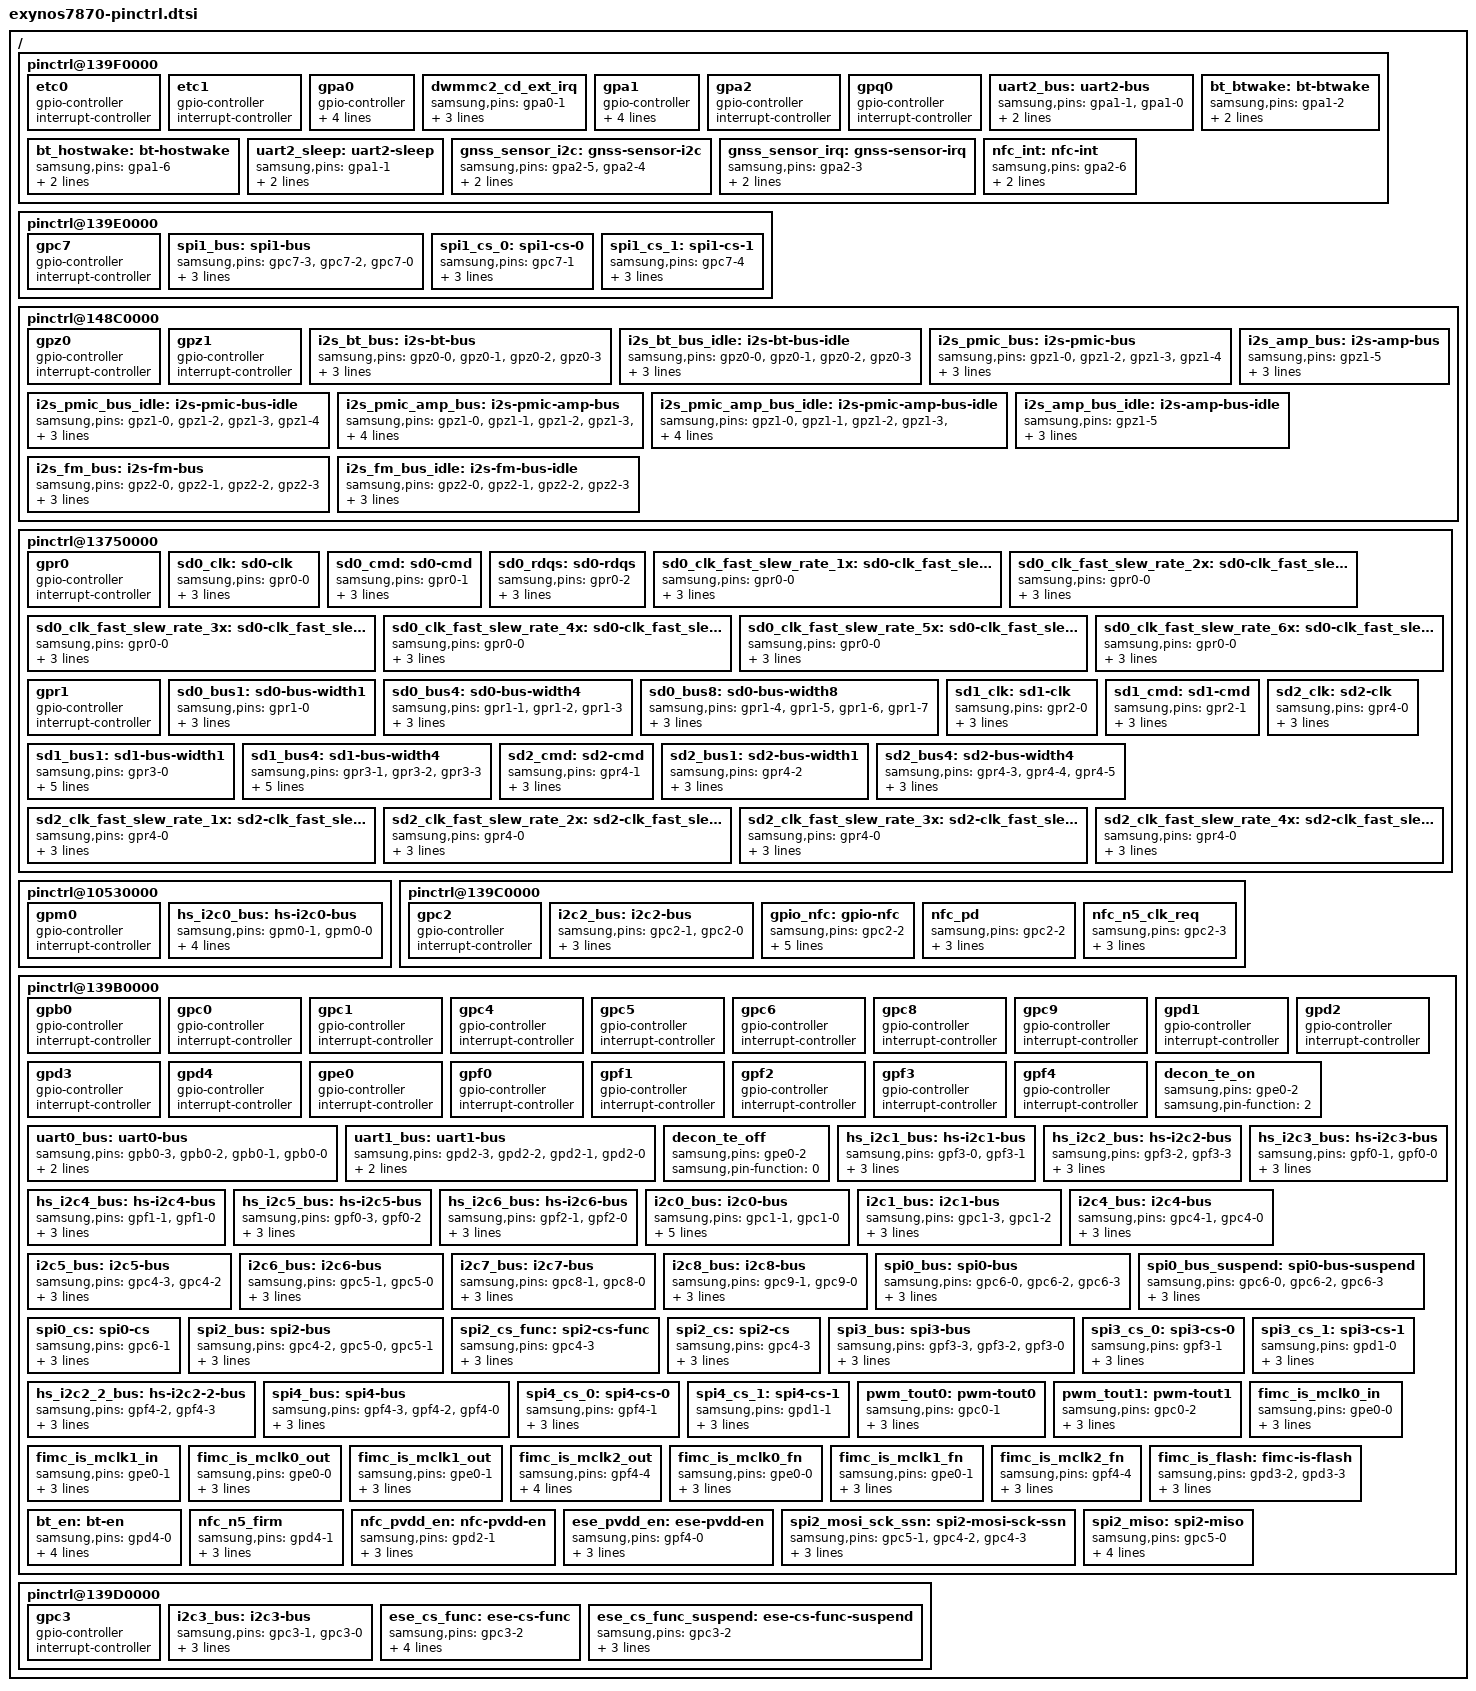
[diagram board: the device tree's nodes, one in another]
/*
 * Samsung's Exynos7870 SoC pin-mux and pin-config device tree source
 *
 * Copyright (c) 2015 Samsung Electronics Co., Ltd.
 *		http://www.samsung.com
 *
 * Samsung's Exynos7870 SoC pin-mux and pin-config options are listed as device
 * tree nodes are listed in this file.
 *
 * This program is free software; you can redistribute it and/or modify
 * it under the terms of the GNU General Public License version 2 as
 * published by the Free Software Foundation.
*/

/ {
	/* ALIVE */
	pinctrl@139F0000 {
		etc0: etc0 {
			gpio-controller;
			#gpio-cells = <2>;

			interrupt-controller;
			#interrupt-cells = <2>;
		};

		etc1: etc1 {
			gpio-controller;
			#gpio-cells = <2>;

			interrupt-controller;
			#interrupt-cells = <2>;
		};

		gpa0: gpa0 {
			gpio-controller;
			#gpio-cells = <2>;

			interrupt-controller;
			#interrupt-cells = <3>;
			interrupt-parent = <&gic>;
			interrupts = <0 0 0>, <0 1 0>, <0 2 0>, <0 3 0>,
				     <0 4 0>, <0 5 0>, <0 6 0>, <0 7 0>;
		};

		dwmmc2_cd_ext_irq: dwmmc2_cd_ext_irq {
			samsung,pins = "gpa0-1";
			samsung,pin-function = <0xf>;
			samsung,pin-pud = <3>;
			samsung,pin-drv = <4>;
		};

		gpa1: gpa1 {
			gpio-controller;
			#gpio-cells = <2>;

			interrupt-controller;
			#interrupt-cells = <3>;
			interrupt-parent = <&gic>;
			interrupts = <0 8 0>, <0 9 0>, <0 10 0>, <0 11 0>,
				     <0 12 0>, <0 13 0>, <0 14 0>, <0 15 0>;
		};

		gpa2: gpa2 {
			gpio-controller;
			#gpio-cells = <2>;

			interrupt-controller;
			#interrupt-cells = <2>;
		};

		gpq0: gpq0 {
			gpio-controller;
			#gpio-cells = <2>;

			interrupt-controller;
			#interrupt-cells = <2>;
		};

		/* UART_DEBUG */
		uart2_bus: uart2-bus {
			samsung,pins = "gpa1-1", "gpa1-0";
			samsung,pin-function = <2>;
			samsung,pin-pud = <0>;
		};

		bt_btwake: bt-btwake {
			samsung,pins = "gpa1-2";
			samsung,pin-function = <1>;
			samsung,pin-pud = <1>;
		};

		bt_hostwake: bt-hostwake {
			samsung,pins = "gpa1-6";
			samsung,pin-function = <0>;
			samsung,pin-pud = <0>;
		};

		uart2_sleep: uart2-sleep {
			samsung,pins = "gpa1-1";
			samsung,pin-function = <0>;
			samsung,pin-pud = <1>;
		};

		gnss_sensor_i2c: gnss-sensor-i2c {
			samsung,pins = "gpa2-5", "gpa2-4";
			samsung,pin-function = <6>;
			samsung,pin-pud = <0>;
		};

		gnss_sensor_irq: gnss-sensor-irq {
			samsung,pins = "gpa2-3";
			samsung,pin-function = <6>;
			samsung,pin-pud = <3>;
		};
		nfc_int: nfc-int {
			samsung,pins = "gpa2-6";
			samsung,pin-function = <0>;
			samsung,pin-pud = <1>;
		};
	};

	pinctrl@139E0000 {
		gpc7: gpc7 {
			gpio-controller;
			#gpio-cells = <2>;

			interrupt-controller;
			#interrupt-cells = <2>;
		};

		spi1_bus: spi1-bus {
			samsung,pins = "gpc7-3", "gpc7-2", "gpc7-0";
			samsung,pin-function = <2>;
			samsung,pin-pud = <3>;
			samsung,pin-drv = <2>;
		};

		spi1_cs_0: spi1-cs-0 {
			samsung,pins = "gpc7-1";
			samsung,pin-function = <1>;
			samsung,pin-pud = <3>;
			samsung,pin-drv = <2>;
		};

		spi1_cs_1: spi1-cs-1 {
			samsung,pins = "gpc7-4";
			samsung,pin-function = <1>;
			samsung,pin-pud = <3>;
			samsung,pin-drv = <0>;
		};
	};


	pinctrl@148C0000 {
		gpz0: gpz0 {
			gpio-controller;
			#gpio-cells = <2>;

			interrupt-controller;
			#interrupt-cells = <2>;
		};

		gpz1: gpz1 {
			gpio-controller;
			#gpio-cells = <2>;

			interrupt-controller;
			#interrupt-cells = <2>;
		};

		i2s_bt_bus: i2s-bt-bus {
			samsung,pins = "gpz0-0", "gpz0-1", "gpz0-2", "gpz0-3";
			samsung,pin-function = <2>;
			samsung,pin-pud = <3>;
			samsung,pin-drv = <2>;
		};

		i2s_bt_bus_idle: i2s-bt-bus-idle {
			samsung,pins = "gpz0-0", "gpz0-1", "gpz0-2", "gpz0-3";
			samsung,pin-function = <0>;
			samsung,pin-pud = <3>;
			samsung,pin-drv = <2>;
		};

		i2s_pmic_bus: i2s-pmic-bus {
			samsung,pins = "gpz1-0", "gpz1-2", "gpz1-3", "gpz1-4";
			samsung,pin-function = <2>;
			samsung,pin-pud = <3>;
			samsung,pin-drv = <5>;
		};

		i2s_pmic_bus_idle: i2s-pmic-bus-idle {
			samsung,pins = "gpz1-0", "gpz1-2", "gpz1-3", "gpz1-4";
			samsung,pin-function = <0>;
			samsung,pin-pud = <3>;
			samsung,pin-drv = <5>;
		};

		i2s_pmic_amp_bus: i2s-pmic-amp-bus {
			samsung,pins = "gpz1-0", "gpz1-1", "gpz1-2", "gpz1-3", "gpz1-4";
			samsung,pin-function = <2>;
			samsung,pin-pud = <3>;
			samsung,pin-drv = <5>;
		};

		i2s_pmic_amp_bus_idle: i2s-pmic-amp-bus-idle {
			samsung,pins = "gpz1-0", "gpz1-1", "gpz1-2", "gpz1-3", "gpz1-4";
			samsung,pin-function = <0>;
			samsung,pin-pud = <3>;
			samsung,pin-drv = <5>;
		};

		i2s_amp_bus: i2s-amp-bus {
			samsung,pins = "gpz1-5";
			samsung,pin-function = <2>;
			samsung,pin-pud = <3>;
			samsung,pin-drv = <2>;
		};

		i2s_amp_bus_idle: i2s-amp-bus-idle {
			samsung,pins = "gpz1-5";
			samsung,pin-function = <0>;
			samsung,pin-pud = <3>;
			samsung,pin-drv = <2>;
		};

		i2s_fm_bus: i2s-fm-bus {
			samsung,pins = "gpz2-0", "gpz2-1", "gpz2-2", "gpz2-3";
			samsung,pin-function = <2>;
			samsung,pin-pud = <0>;
			samsung,pin-drv = <2>;
		};

		i2s_fm_bus_idle: i2s-fm-bus-idle {
			samsung,pins = "gpz2-0", "gpz2-1", "gpz2-2", "gpz2-3";
			samsung,pin-function = <0>;
			samsung,pin-pud = <0>;
			samsung,pin-drv = <2>;
		};
	};

	/* FSYS */
	pinctrl@13750000 {
		gpr0: gpr0 {
			gpio-controller;
			#gpio-cells = <2>;

			interrupt-controller;
			#interrupt-cells = <2>;
		};

		sd0_clk: sd0-clk {
			samsung,pins = "gpr0-0";
			samsung,pin-function = <2>;
			samsung,pin-pud = <0>;
			samsung,pin-drv = <2>;
		};

		sd0_cmd: sd0-cmd {
			samsung,pins = "gpr0-1";
			samsung,pin-function = <2>;
			samsung,pin-pud = <3>;
			samsung,pin-drv = <2>;
		};

		sd0_rdqs: sd0-rdqs {
			samsung,pins = "gpr0-2";
			samsung,pin-function = <2>;
			samsung,pin-pud = <0>;
			samsung,pin-drv = <2>;
		};

		sd0_clk_fast_slew_rate_1x: sd0-clk_fast_slew_rate_1x {
			samsung,pins = "gpr0-0";
			samsung,pin-function = <2>;
			samsung,pin-pud = <0>;
			samsung,pin-drv = <0>;
		};

		sd0_clk_fast_slew_rate_2x: sd0-clk_fast_slew_rate_2x {
			samsung,pins = "gpr0-0";
			samsung,pin-function = <2>;
			samsung,pin-pud = <0>;
			samsung,pin-drv = <1>;
		};

		sd0_clk_fast_slew_rate_3x: sd0-clk_fast_slew_rate_3x {
			samsung,pins = "gpr0-0";
			samsung,pin-function = <2>;
			samsung,pin-pud = <0>;
			samsung,pin-drv = <2>;
		};

		sd0_clk_fast_slew_rate_4x: sd0-clk_fast_slew_rate_4x {
			samsung,pins = "gpr0-0";
			samsung,pin-function = <2>;
			samsung,pin-pud = <0>;
			samsung,pin-drv = <3>;
		};

		sd0_clk_fast_slew_rate_5x: sd0-clk_fast_slew_rate_5x {
			samsung,pins = "gpr0-0";
			samsung,pin-function = <2>;
			samsung,pin-pud = <0>;
			samsung,pin-drv = <4>;
		};

		sd0_clk_fast_slew_rate_6x: sd0-clk_fast_slew_rate_6x {
			samsung,pins = "gpr0-0";
			samsung,pin-function = <2>;
			samsung,pin-pud = <0>;
			samsung,pin-drv = <5>;
		};

		gpr1: gpr1 {
			gpio-controller;
			#gpio-cells = <2>;

			interrupt-controller;
			#interrupt-cells = <2>;
		};

		sd0_bus1: sd0-bus-width1 {
			samsung,pins = "gpr1-0";
			samsung,pin-function = <2>;
			samsung,pin-pud = <3>;
			samsung,pin-drv = <2>;
		};

		sd0_bus4: sd0-bus-width4 {
			samsung,pins = "gpr1-1", "gpr1-2", "gpr1-3";
			samsung,pin-function = <2>;
			samsung,pin-pud = <3>;
			samsung,pin-drv = <2>;
		};

		sd0_bus8: sd0-bus-width8 {
			samsung,pins = "gpr1-4", "gpr1-5", "gpr1-6", "gpr1-7";
			samsung,pin-function = <2>;
			samsung,pin-pud = <3>;
			samsung,pin-drv = <2>;
		};

		sd1_clk: sd1-clk {
			samsung,pins = "gpr2-0";
			samsung,pin-function = <2>;
			samsung,pin-pud = <0>;
			samsung,pin-drv = <2>;
		};

		sd1_cmd: sd1-cmd {
			samsung,pins = "gpr2-1";
			samsung,pin-function = <2>;
			samsung,pin-pud = <0>;
			samsung,pin-drv = <2>;
		};

		sd1_bus1: sd1-bus-width1 {
			samsung,pins = "gpr3-0";
			samsung,pin-function = <2>;
			samsung,pin-pud = <3>;
			samsung,pin-drv = <2>;
			samsung,pin-con-pdn = <2>;
			samsung,pin-pud-pdn = <3>;
		};

		sd1_bus4: sd1-bus-width4 {
			samsung,pins = "gpr3-1", "gpr3-2", "gpr3-3";
			samsung,pin-function = <2>;
			samsung,pin-pud = <3>;
			samsung,pin-drv = <2>;
			samsung,pin-con-pdn = <2>;
			samsung,pin-pud-pdn = <3>;
		};

		sd2_clk: sd2-clk {
			samsung,pins = "gpr4-0";
			samsung,pin-function = <2>;
			samsung,pin-pud = <0>;
			samsung,pin-drv = <2>;
		};

		sd2_cmd: sd2-cmd {
			samsung,pins = "gpr4-1";
			samsung,pin-function = <2>;
			samsung,pin-pud = <3>;
			samsung,pin-drv = <2>;
		};

		sd2_bus1: sd2-bus-width1 {
			samsung,pins = "gpr4-2";
			samsung,pin-function = <2>;
			samsung,pin-pud = <3>;
			samsung,pin-drv = <2>;
		};

		sd2_bus4: sd2-bus-width4 {
			samsung,pins = "gpr4-3", "gpr4-4", "gpr4-5";
			samsung,pin-function = <2>;
			samsung,pin-pud = <3>;
			samsung,pin-drv = <2>;
		};

		sd2_clk_fast_slew_rate_1x: sd2-clk_fast_slew_rate_1x {
			samsung,pins = "gpr4-0";
			samsung,pin-function = <2>;
			samsung,pin-pud = <0>;
			samsung,pin-drv = <0>;
		};

		sd2_clk_fast_slew_rate_2x: sd2-clk_fast_slew_rate_2x {
			samsung,pins = "gpr4-0";
			samsung,pin-function = <2>;
			samsung,pin-pud = <0>;
			samsung,pin-drv = <1>;
		};

		sd2_clk_fast_slew_rate_3x: sd2-clk_fast_slew_rate_3x {
			samsung,pins = "gpr4-0";
			samsung,pin-function = <2>;
			samsung,pin-pud = <0>;
			samsung,pin-drv = <2>;
		};

		sd2_clk_fast_slew_rate_4x: sd2-clk_fast_slew_rate_4x {
			samsung,pins = "gpr4-0";
			samsung,pin-function = <2>;
			samsung,pin-pud = <0>;
			samsung,pin-drv = <3>;
		};
	};

	/* MIF */
	pinctrl@10530000 {
		gpm0: gpm0 {
			gpio-controller;
			#gpio-cells = <2>;

			interrupt-controller;
			#interrupt-cells = <2>;
		};

		/* HSI2C_MIF_AP */
		hs_i2c0_bus: hs-i2c0-bus {
			samsung,pins = "gpm0-1", "gpm0-0";
			samsung,pin-function = <2>;
			samsung,pin-pud = <0>;
			samsung,pin-drv = <0>;
			samsung,pin-con-pdn = <3>;
		};
	};

	/* NFC */
	pinctrl@139C0000 {
		gpc2: gpc2 {
			gpio-controller;
			#gpio-cells = <2>;

			interrupt-controller;
			#interrupt-cells = <2>;
		};

		/* I2C_NFC */
		i2c2_bus: i2c2-bus {
			samsung,pins = "gpc2-1", "gpc2-0";
			samsung,pin-function = <2>;
			samsung,pin-pud = <0>;
			samsung,pin-drv = <0>;
		};

		gpio_nfc: gpio-nfc {
			samsung,pins = "gpc2-2";
			samsung,pin-function = <0x1>;
			samsung,pin-pud = <0>;
			samsung,pin-drv = <0>;
			samsung,pin-con-pdn = <3>;
			samsung,pin-val = <1>;
		};
		nfc_pd: nfc_pd {
			samsung,pins = "gpc2-2";
			samsung,pin-function = <2>;
			samsung,pin-pud = <3>;
			samsung,pin-drv = <0>;
		};

		nfc_n5_clk_req: nfc_n5_clk_req {
			samsung,pins = "gpc2-3";
			samsung,pin-function = <2>;
			samsung,pin-pud = <1>;
			samsung,pin-drv = <0>;
		};
	};

	/* TOP */
	pinctrl@139B0000 {
		gpb0: gpb0 {
			gpio-controller;
			#gpio-cells = <2>;

			interrupt-controller;
			#interrupt-cells = <2>;
		};

		gpc0: gpc0 {
			gpio-controller;
			#gpio-cells = <2>;

			interrupt-controller;
			#interrupt-cells = <2>;
		};

		gpc1: gpc1 {
			gpio-controller;
			#gpio-cells = <2>;

			interrupt-controller;
			#interrupt-cells = <2>;
		};

		gpc4: gpc4 {
			gpio-controller;
			#gpio-cells = <2>;

			interrupt-controller;
			#interrupt-cells = <2>;
		};

		gpc5: gpc5 {
			gpio-controller;
			#gpio-cells = <2>;

			interrupt-controller;
			#interrupt-cells = <2>;
		};

		gpc6: gpc6 {
			gpio-controller;
			#gpio-cells = <2>;

			interrupt-controller;
			#interrupt-cells = <2>;
		};

		gpc8: gpc8 {
			gpio-controller;
			#gpio-cells = <2>;

			interrupt-controller;
			#interrupt-cells = <2>;
		};

		gpc9: gpc9 {
			gpio-controller;
			#gpio-cells = <2>;

			interrupt-controller;
			#interrupt-cells = <2>;
		};

		gpd1: gpd1 {
			gpio-controller;
			#gpio-cells = <2>;

			interrupt-controller;
			#interrupt-cells = <2>;
		};

		gpd2: gpd2 {
			gpio-controller;
			#gpio-cells = <2>;

			interrupt-controller;
			#interrupt-cells = <2>;
		};

		gpd3: gpd3 {
			gpio-controller;
			#gpio-cells = <2>;

			interrupt-controller;
			#interrupt-cells = <2>;
		};

		gpd4: gpd4 {
			gpio-controller;
			#gpio-cells = <2>;

			interrupt-controller;
			#interrupt-cells = <2>;
		};

		gpe0: gpe0 {
			gpio-controller;
			#gpio-cells = <2>;

			interrupt-controller;
			#interrupt-cells = <2>;
		};

		gpf0: gpf0 {
			gpio-controller;
			#gpio-cells = <2>;

			interrupt-controller;
			#interrupt-cells = <2>;
		};

		gpf1: gpf1 {
			gpio-controller;
			#gpio-cells = <2>;

			interrupt-controller;
			#interrupt-cells = <2>;
		};

		gpf2: gpf2 {
			gpio-controller;
			#gpio-cells = <2>;

			interrupt-controller;
			#interrupt-cells = <2>;
		};

		gpf3: gpf3 {
			gpio-controller;
			#gpio-cells = <2>;

			interrupt-controller;
			#interrupt-cells = <2>;
		};

		gpf4: gpf4 {
			gpio-controller;
			#gpio-cells = <2>;

			interrupt-controller;
			#interrupt-cells = <2>;
		};

		/* UART_BTWIFIFM */
		uart0_bus: uart0-bus {
			samsung,pins = "gpb0-3", "gpb0-2", "gpb0-1", "gpb0-0";
			samsung,pin-function = <2>;
			samsung,pin-pud = <0>;
		};

		/* UART_SENSOR */
		uart1_bus: uart1-bus {
			samsung,pins = "gpd2-3", "gpd2-2", "gpd2-1", "gpd2-0";
			samsung,pin-function = <2>;
			samsung,pin-pud = <0>;
		};

		/* TE SIGNAL */
		decon_te_on: decon_te_on {
			samsung,pins = "gpe0-2";
			samsung,pin-function = <2>;
		};

		decon_te_off: decon_te_off {
			samsung,pins = "gpe0-2";
			samsung,pin-function = <0>;
		};

		/* HSI2C_MAINCAM */
		hs_i2c1_bus: hs-i2c1-bus {
			samsung,pins = "gpf3-0", "gpf3-1";
			samsung,pin-function = <3>;
			samsung,pin-pud = <0>;
			samsung,pin-drv = <0>;
		};

		/* HSI2C_FRONTCAM */
		hs_i2c2_bus: hs-i2c2-bus {
			samsung,pins = "gpf3-2", "gpf3-3";
			samsung,pin-function = <3>;
			samsung,pin-pud = <0>;
			samsung,pin-drv = <0>;
		};

		/* HSI2C_REARSENSOR */
		hs_i2c3_bus: hs-i2c3-bus {
			samsung,pins = "gpf0-1", "gpf0-0";
			samsung,pin-function = <2>;
			samsung,pin-pud = <0>;
			samsung,pin-drv = <0>;
		};

		/* HSI2C_REARAF */
		hs_i2c4_bus: hs-i2c4-bus {
			samsung,pins = "gpf1-1", "gpf1-0";
			samsung,pin-function = <2>;
			samsung,pin-pud = <0>;
			samsung,pin-drv = <0>;
		};

		/* HSI2C_FRONTSENSOR */
		hs_i2c5_bus: hs-i2c5-bus {
			samsung,pins = "gpf0-3", "gpf0-2";
			samsung,pin-function = <2>;
			samsung,pin-pud = <0>;
			samsung,pin-drv = <0>;
		};

		/* HSI2C_DEPTHCAM */
		hs_i2c6_bus: hs-i2c6-bus {
			samsung,pins = "gpf2-1", "gpf2-0";
			samsung,pin-function = <2>;
			samsung,pin-pud = <0>;
			samsung,pin-drv = <0>;
		};

		/* I2C_IFPMIC */
		i2c0_bus: i2c0-bus {
			samsung,pins = "gpc1-1", "gpc1-0";
			samsung,pin-function = <2>;
			samsung,pin-pud = <3>;
			samsung,pin-drv = <0>;
			samsung,pin-con-pdn = <3>;
			samsung,pin-pud-pdn = <3>;
		};

		/* I2C_MUIC */
		i2c1_bus: i2c1-bus {
			samsung,pins = "gpc1-3", "gpc1-2";
			samsung,pin-function = <2>;
			samsung,pin-pud = <3>;
			samsung,pin-drv = <0>;
		};

		/* I2C_FUELGAUGE */
		i2c4_bus: i2c4-bus {
			samsung,pins = "gpc4-1", "gpc4-0";
			samsung,pin-function = <2>;
			samsung,pin-pud = <3>;
			samsung,pin-drv = <0>;
		};

		/* I2C_SENSOR1 */
		i2c5_bus: i2c5-bus {
			samsung,pins = "gpc4-3", "gpc4-2";
			samsung,pin-function = <2>;
			samsung,pin-pud = <3>;
			samsung,pin-drv = <0>;
		};

		/* I2C_SENSOR2 */
		i2c6_bus: i2c6-bus {
			samsung,pins = "gpc5-1", "gpc5-0";
			samsung,pin-function = <2>;
			samsung,pin-pud = <3>;
			samsung,pin-drv = <0>;
		};

		/* I2C_TOUCHKEY */
		i2c7_bus: i2c7-bus {
			samsung,pins = "gpc8-1", "gpc8-0";
			samsung,pin-function = <2>;
			samsung,pin-pud = <0>;
			samsung,pin-drv = <0>;
		};

		/* I2C_SPKAMP */
		i2c8_bus: i2c8-bus {
			samsung,pins = "gpc9-1", "gpc9-0";
			samsung,pin-function = <2>;
			samsung,pin-pud = <3>;
			samsung,pin-drv = <0>;
		};

		/* SPI_ESE */
		spi0_bus: spi0-bus {
			samsung,pins = "gpc6-0", "gpc6-2", "gpc6-3";
			samsung,pin-function = <2>;
			samsung,pin-pud = <3>;
			samsung,pin-drv = <0>;
		};

		spi0_bus_suspend: spi0-bus-suspend {
			samsung,pins = "gpc6-0", "gpc6-2", "gpc6-3";
			samsung,pin-function = <0>; /* IN */
			samsung,pin-pud = <1>; /* PD */
			samsung,pin-drv = <0>;
		};

		spi0_cs: spi0-cs {
			samsung,pins = "gpc6-1";
			samsung,pin-function = <1>;
			samsung,pin-pud = <3>;
			samsung,pin-drv = <0>;
		};

		/* SPI_SENSORHUB */
		spi2_bus: spi2-bus {
			samsung,pins = "gpc4-2", "gpc5-0", "gpc5-1";
			samsung,pin-function = <3>;
			samsung,pin-pud = <3>;
			samsung,pin-drv = <0>;
		};

		spi2_cs_func: spi2-cs-func {
			samsung,pins = "gpc4-3";
			samsung,pin-function = <3>;
			samsung,pin-pud = <3>;
			samsung,pin-drv = <0>;
		};

		spi2_cs: spi2-cs {
			samsung,pins = "gpc4-3";
			samsung,pin-function = <1>;
			samsung,pin-pud = <3>;
			samsung,pin-drv = <0>;
		};

		/* SPI_REARFROM */
		spi3_bus: spi3-bus {
			samsung,pins = "gpf3-3", "gpf3-2", "gpf3-0";
			samsung,pin-function = <2>;
			samsung,pin-pud = <3>;
			samsung,pin-drv = <0>;
		};

		spi3_cs_0: spi3-cs-0 {
			samsung,pins = "gpf3-1";
			samsung,pin-function = <1>;
			samsung,pin-pud = <3>;
			samsung,pin-drv = <0>;
		};

		spi3_cs_1: spi3-cs-1 {
			samsung,pins = "gpd1-0";
			samsung,pin-function = <1>;
			samsung,pin-pud = <3>;
			samsung,pin-drv = <0>;
		};

		/* HSI2C_SPI_FRONTFROM */
		hs_i2c2_2_bus: hs-i2c2-2-bus {
		   samsung,pins = "gpf4-2", "gpf4-3";
		   samsung,pin-function = <3>;
		   samsung,pin-pud = <0>;
		   samsung,pin-drv = <0>;
		};

		/* SPI_FRONTFROM */

		/delete-node/ spi4-bus;
		/delete-node/ spi4-cs-0;

		spi4_bus: spi4-bus {
			samsung,pins = "gpf4-3", "gpf4-2", "gpf4-0";
			samsung,pin-function = <2>;
			samsung,pin-pud = <3>;
			samsung,pin-drv = <0>;
		};

		spi4_cs_0: spi4-cs-0 {
			samsung,pins = "gpf4-1";
			samsung,pin-function = <1>;
			samsung,pin-pud = <3>;
			samsung,pin-drv = <0>;
		};

		spi4_cs_1: spi4-cs-1 {
			samsung,pins = "gpd1-1";
			samsung,pin-function = <1>;
			samsung,pin-pud = <3>;
			samsung,pin-drv = <0>;
		};

		pwm_tout0: pwm-tout0 {
			samsung,pins = "gpc0-1";
			samsung,pin-function = <2>;
			samsung,pin-pud = <1>;
			samsung,pin-drv = <0>;
		};

		pwm_tout1: pwm-tout1 {
			samsung,pins = "gpc0-2";
			samsung,pin-function = <2>;
			samsung,pin-pud = <1>;
			samsung,pin-drv = <0>;
		};

		fimc_is_mclk0_in: fimc_is_mclk0_in {
			samsung,pins = "gpe0-0";
			samsung,pin-function = <0>;
			samsung,pin-pud = <0>;
			samsung,pin-drv = <0>;
		};

		fimc_is_mclk1_in: fimc_is_mclk1_in {
			samsung,pins = "gpe0-1";
			samsung,pin-function = <0>;
			samsung,pin-pud = <0>;
			samsung,pin-drv = <0>;
		};

		fimc_is_mclk0_out: fimc_is_mclk0_out {
			samsung,pins = "gpe0-0";
			samsung,pin-function = <1>;
			samsung,pin-pud = <1>;
			samsung,pin-drv = <2>;
		};

		fimc_is_mclk1_out: fimc_is_mclk1_out {
			samsung,pins = "gpe0-1";
			samsung,pin-function = <1>;
			samsung,pin-pud = <1>;
			samsung,pin-drv = <2>;
		};

		fimc_is_mclk2_out: fimc_is_mclk2_out {
			samsung,pins = "gpf4-4";
			samsung,pin-function = <1>;
			samsung,pin-pud = <0>;
			samsung,pin-drv = <2>;
			samsung,pin-val = <0>;
		};

		fimc_is_mclk0_fn: fimc_is_mclk0_fn {
			samsung,pins = "gpe0-0";
			samsung,pin-function = <2>;
			samsung,pin-pud = <0>;
			samsung,pin-drv = <0>;
		};

		fimc_is_mclk1_fn: fimc_is_mclk1_fn {
			samsung,pins = "gpe0-1";
			samsung,pin-function = <2>;
			samsung,pin-pud = <0>;
			samsung,pin-drv = <1>;
		};

		fimc_is_mclk2_fn: fimc_is_mclk2_fn {
			samsung,pins = "gpf4-4";
			samsung,pin-function = <2>;
			samsung,pin-pud = <0>;
			samsung,pin-drv = <2>;
		};

		fimc_is_flash: fimc-is-flash {
			samsung,pins = "gpd3-2", "gpd3-3";
			samsung,pin-function = <1>;
			samsung,pin-pud = <0>;
			samsung,pin-drv = <0>;
		};

		bt_en: bt-en {
			samsung,pins ="gpd4-0";
			samsung,pin-function = <1>;
			samsung,pin-pud = <1>;
			samsung,pin-con-pdn = <3>;
			samsung,pin-pud-pdn = <0>;
		};

		nfc_n5_firm: nfc_n5_firm {
			samsung,pins = "gpd4-1";
			samsung,pin-function = <1>;
			samsung,pin-pud = <1>;
			samsung,pin-val = <1>;
		};

		nfc_pvdd_en: nfc-pvdd-en {
			samsung,pins = "gpd2-1";
			samsung,pin-function = <1>;
			samsung,pin-pud = <3>;
			samsung,pin-drv = <3>;
		};
		
		ese_pvdd_en: ese-pvdd-en {
			samsung,pins = "gpf4-0";
			samsung,pin-function = <1>;
			samsung,pin-pud = <1>;
			samsung,pin-drv = <3>;
		};
		spi2_mosi_sck_ssn: spi2-mosi-sck-ssn {
			samsung,pins = "gpc5-1", "gpc4-2", "gpc4-3";
			samsung,pin-function = <3>;
			samsung,pin-pud = <3>;
			samsung,pin-drv = <3>;
		};
		spi2_miso: spi2-miso {
			samsung,pins = "gpc5-0";
			samsung,pin-function = <3>;
			samsung,pin-pud = <0>;
			samsung,pin-drv = <3>;
			samsung,pin-pud-pdn = <0>;
		};
	};

	/* TOUCH */
	pinctrl@139D0000 {
		gpc3: gpc3 {
			gpio-controller;
			#gpio-cells = <2>;

			interrupt-controller;
			#interrupt-cells = <2>;
		};

		/* I2C_TSP */
		i2c3_bus: i2c3-bus {
			samsung,pins = "gpc3-1", "gpc3-0";
			samsung,pin-function = <2>;
			samsung,pin-pud = <3>;
			samsung,pin-drv = <0>;
		};

		/*SPI_ESE*/
		ese_cs_func: ese-cs-func {
			samsung,pins ="gpc3-2";
			samsung,pin-function = <1>; /* OUT */
			samsung,pin-pud = <0>; /* NP */
			samsung,pin-drv = <0>;
			samsung,pin-val = <1>; /* HIGH */
		};

		ese_cs_func_suspend: ese-cs-func-suspend {
			samsung,pins ="gpc3-2";
			samsung,pin-function = <0>; /* IN */
			samsung,pin-pud = <1>; /* PD */
			samsung,pin-drv = <0>;
		};
	};
};
